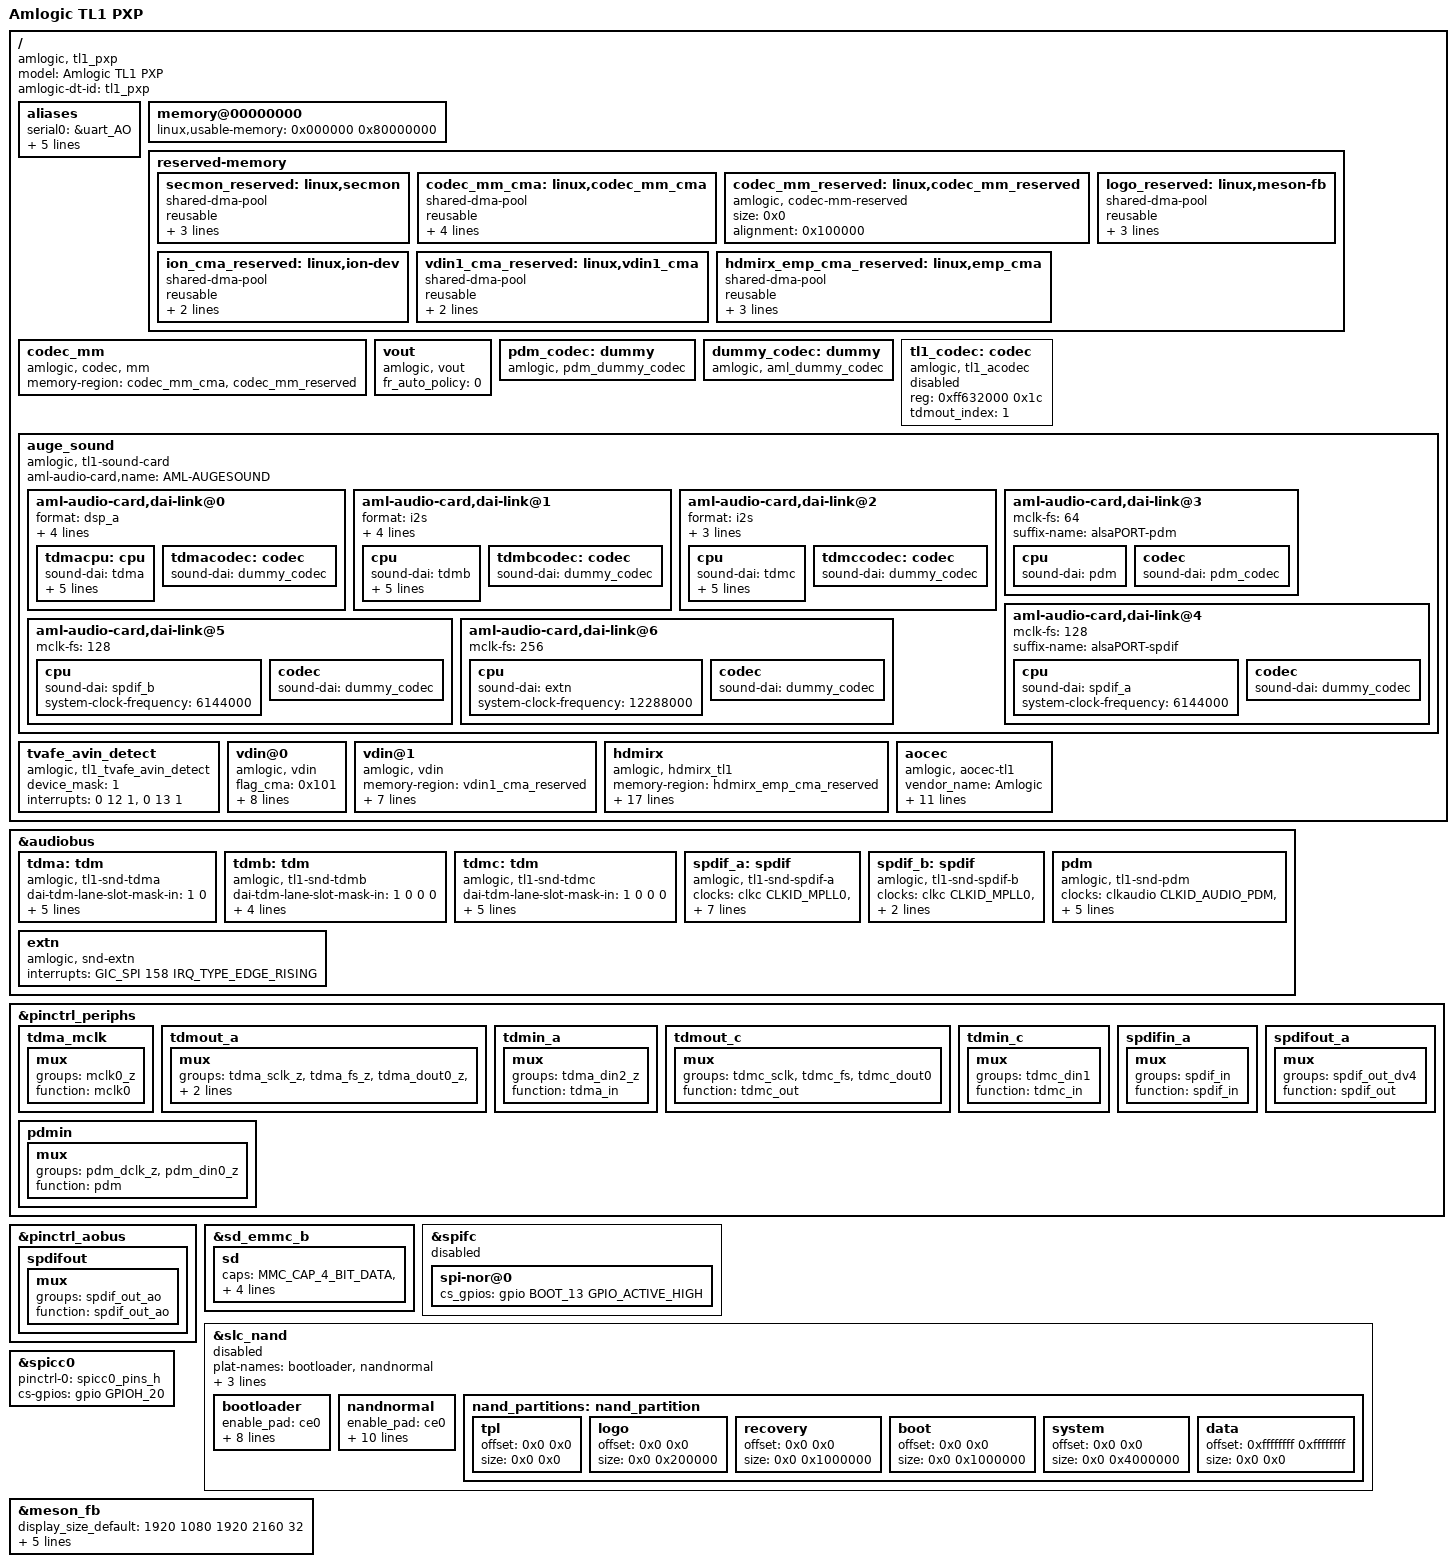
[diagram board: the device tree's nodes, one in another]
/*
 * arch/arm/boot/dts/amlogic/tl1_pxp.dts
 *
 * Copyright (C) 2018 Amlogic, Inc. All rights reserved.
 *
 * This program is free software; you can redistribute it and/or modify
 * it under the terms of the GNU General Public License as published by
 * the Free Software Foundation; either version 2 of the License, or
 * (at your option) any later version.
 *
 * This program is distributed in the hope that it will be useful, but WITHOUT
 * ANY WARRANTY; without even the implied warranty of MERCHANTABILITY or
 * FITNESS FOR A PARTICULAR PURPOSE.  See the GNU General Public License for
 * more details.
 *
 */

/dts-v1/;
#include "mesontl1.dtsi"

/ {
	model = "Amlogic TL1 PXP";
	amlogic-dt-id = "tl1_pxp";
	compatible = "amlogic, tl1_pxp";

	aliases {
		serial0 = &uart_AO;
		i2c0 = &i2c0;
		i2c1 = &i2c1;
		i2c2 = &i2c2;
		i2c3 = &i2c3;
		i2c4 = &i2c_AO;
	};

	memory@00000000 {
		device_type = "memory";
		linux,usable-memory = <0x000000 0x80000000>;
	};

	reserved-memory {
		#address-cells = <1>;
		#size-cells = <1>;
		ranges;
		/* global autoconfigured region for contiguous allocations */
		secmon_reserved: linux,secmon {
			compatible = "shared-dma-pool";
			reusable;
			size = <0x400000>;
			alignment = <0x400000>;
			alloc-ranges = <0x05000000 0x400000>;
		};

		codec_mm_cma:linux,codec_mm_cma {
			compatible = "shared-dma-pool";
			reusable;
			/* ion_codec_mm max can alloc size 80M*/
			size = <0x13400000>;
			alignment = <0x400000>;
			linux,contiguous-region;
			alloc-ranges = <0x30000000 0x50000000>;
		};

		/* codec shared reserved */
		codec_mm_reserved:linux,codec_mm_reserved {
			compatible = "amlogic, codec-mm-reserved";
			size = <0x0>;
			alignment = <0x100000>;
			//no-map;
		};

		logo_reserved:linux,meson-fb {
			compatible = "shared-dma-pool";
			reusable;
			size = <0x800000>;
			alignment = <0x400000>;
			alloc-ranges = <0x7f800000 0x800000>;
		};

		ion_cma_reserved:linux,ion-dev {
			compatible = "shared-dma-pool";
			reusable;
			size = <0x8000000>;
			alignment = <0x400000>;
		};

		/*  vdin0 CMA pool */
		//vdin0_cma_reserved:linux,vdin0_cma {
		//	compatible = "shared-dma-pool";
		//	reusable;
			/* 3840x2160x4x4 ~=128 M */
		//	size = <0xc400000>;
		//	alignment = <0x400000>;
		//};

		/*  vdin1 CMA pool */
		vdin1_cma_reserved:linux,vdin1_cma {
			compatible = "shared-dma-pool";
			reusable;
			/* 1920x1080x2x4  =16 M */
			size = <0x1400000>;
			alignment = <0x400000>;
		};

		/* for hdmi rx emp use */
		hdmirx_emp_cma_reserved:linux,emp_cma {
			compatible = "shared-dma-pool";
			/*linux,phandle = <5>;*/
			reusable;
			/* 2M-30M for emp or tmds to ddr */
			size = <0x01e00000>;
			alignment = <0x10000>;
			alloc-ranges = <0x30000000 0x50000000>;
		};
	}; /* end of reserved-memory */

	codec_mm {
		compatible = "amlogic, codec, mm";
		status = "okay";
		memory-region = <&codec_mm_cma &codec_mm_reserved>;
	};

	vout {
		compatible = "amlogic, vout";
		status = "okay";
		fr_auto_policy = <0>;
	};

	/* Audio Related start */
	pdm_codec:dummy {
		#sound-dai-cells = <0>;
		compatible = "amlogic, pdm_dummy_codec";
		status = "okay";
	};

	dummy_codec:dummy {
		#sound-dai-cells = <0>;
		compatible = "amlogic, aml_dummy_codec";
		status = "okay";
	};

	tl1_codec:codec {
		#sound-dai-cells = <0>;
		compatible = "amlogic, tl1_acodec";
		status = "disabled";
		reg = <0xff632000 0x1c>;
		tdmout_index = <1>;
	};

	auge_sound {
		compatible = "amlogic, tl1-sound-card";
		aml-audio-card,name = "AML-AUGESOUND";

		aml-audio-card,dai-link@0 {
			format = "dsp_a";
			mclk-fs = <512>;
			//continuous-clock;
			//bitclock-inversion;
			//frame-inversion;
			/* master mode */
			bitclock-master = <&tdma>;
			frame-master = <&tdma>;
			/* slave mode */
			/*
			 * bitclock-master = <&tdmacodec>;
			 * frame-master = <&tdmacodec>;
			 */
			/* suffix-name, sync with android audio hal used for */
			suffix-name = "alsaPORT-pcm";
			tdmacpu: cpu {
				sound-dai = <&tdma>;
				dai-tdm-slot-tx-mask =
							<1 1 1 1 1 1 1 1>;
				dai-tdm-slot-rx-mask =
							<1 1 1 1 1 1 1 1>;
				dai-tdm-slot-num = <8>;
				dai-tdm-slot-width = <32>;
				system-clock-frequency = <24576000>;
			};
			tdmacodec: codec {
				sound-dai = <&dummy_codec>;
			};
		};

		aml-audio-card,dai-link@1 {
			format = "i2s";
			mclk-fs = <256>;
			//continuous-clock;
			//bitclock-inversion;
			//frame-inversion;
			/* master mode */
			bitclock-master = <&tdmb>;
			frame-master = <&tdmb>;
			/* slave mode */
			//bitclock-master = <&tdmbcodec>;
			//frame-master = <&tdmbcodec>;
			/* suffix-name, sync with android audio hal used for */
			suffix-name = "alsaPORT-i2s";
			cpu {
				sound-dai = <&tdmb>;
				dai-tdm-slot-tx-mask = <1 1>;
				dai-tdm-slot-rx-mask = <1 1>;
				dai-tdm-slot-num = <2>;
				/*
				 * dai-tdm-slot-tx-mask =
				 *	<1 1 1 1 1 1 1 1>;
				 * dai-tdm-slot-rx-mask =
				 *	<1 1 1 1 1 1 1 1>;
				 * dai-tdm-slot-num = <8>;
				 */
				dai-tdm-slot-width = <32>;
				system-clock-frequency = <12288000>;
			};
			tdmbcodec: codec {
				sound-dai = <&dummy_codec>;
			};
		};

		aml-audio-card,dai-link@2 {
			format = "i2s";
			mclk-fs = <256>;
			//continuous-clock;
			//bitclock-inversion;
			//frame-inversion;
			/* master mode */
			bitclock-master = <&tdmc>;
			frame-master = <&tdmc>;
			/* slave mode */
			//bitclock-master = <&tdmccodec>;
			//frame-master = <&tdmccodec>;
			/* suffix-name, sync with android audio hal used for */
			//suffix-name = "alsaPORT-tdm";
			cpu {
				sound-dai = <&tdmc>;
				dai-tdm-slot-tx-mask = <1 1>;
				dai-tdm-slot-rx-mask = <1 1>;
				dai-tdm-slot-num = <2>;
				dai-tdm-slot-width = <32>;
				system-clock-frequency = <12288000>;
			};
			tdmccodec: codec {
				sound-dai = <&dummy_codec>;
			};
		};

		aml-audio-card,dai-link@3 {
			mclk-fs = <64>;
			/* suffix-name, sync with android audio hal used for */
			suffix-name = "alsaPORT-pdm";
			cpu {
				sound-dai = <&pdm>;
			};
			codec {
				sound-dai = <&pdm_codec>;
			};
		};

		aml-audio-card,dai-link@4 {
			mclk-fs = <128>;
			/* suffix-name, sync with android audio hal used for */
			suffix-name = "alsaPORT-spdif";
			cpu {
				sound-dai = <&spdif_a>;
				system-clock-frequency = <6144000>;
			};
			codec {
				sound-dai = <&dummy_codec>;
			};
		};

		aml-audio-card,dai-link@5 {
			mclk-fs = <128>;
			cpu {
				sound-dai = <&spdif_b>;
				system-clock-frequency = <6144000>;
			};
			codec {
				sound-dai = <&dummy_codec>;
			};
		};

		aml-audio-card,dai-link@6 {
			mclk-fs = <256>;
			cpu {
				sound-dai = <&extn>;
				system-clock-frequency = <12288000>;
			};
			codec {
				sound-dai = <&dummy_codec>;
			};
		};

	};
	/* Audio Related end */

	tvafe_avin_detect {
		compatible = "amlogic, tl1_tvafe_avin_detect";
		status = "okay";
		device_mask = <1>;/*bit0:ch1;bit1:ch2*/
		interrupts = <0 12 1>,
				<0 13 1>;
	};

	vdin@0 {
		compatible = "amlogic, vdin";
		/*memory-region = <&vdin0_cma_reserved>;*/
		status = "okay";
		/*bit0:(1:share with codec_mm;0:cma alone)
		 *bit8:(1:alloc in discontinus way;0:alone in continuous way)
		 */
		flag_cma = <0x101>;
		/*MByte, if 10bit disable: 64M(YUV422),
		 *if 10bit enable: 64*1.5 = 96M(YUV422)
		 *if support 4K2K-YUV444-10bit-WR:3840*2160*4*4 ~= 128M
		 *if support 4K2K-YUV422-10bit-wr:3840*2160*3*4 ~= 96M
		 *if support 4K2K-YUV422-8BIT-WR:3840*2160*2*4 ~= 64M
		 *if support 1080p-YUV422-8BIT-WR:1920*1080*2*4 ~= 16M
		 */
		cma_size = <190>;
		interrupts = <0 83 1>;
		rdma-irq = <2>;
		clocks = <&clkc CLKID_FCLK_DIV5>,
			<&clkc CLKID_VDIN_MEAS_COMP>;
		clock-names = "fclk_div5", "cts_vdin_meas_clk";
		vdin_id = <0>;
		/*vdin write mem color depth support:
		 * bit0:support 8bit
		 * bit1:support 9bit
		 * bit2:support 10bit
		 * bit3:support 12bit
		 * bit4:support yuv422 10bit full pack mode (from txl new add)
		 * bit8:use 8bit  at 4k_50/60hz_10bit
		 * bit9:use 10bit at 4k_50/60hz_10bit
		 */
		tv_bit_mode = <0x215>;
		/* afbce_bit_mode: (amlogic frame buff compression encoder)
		 * 0: normal mode, not use afbce
		 * 1: use afbce non-mmu mode
		 * 2: use afbce mmu mode
		 */
		afbce_bit_mode = <0>;
	};

	vdin@1 {
		compatible = "amlogic, vdin";
		memory-region = <&vdin1_cma_reserved>;
		status = "okay";
		/*bit0:(1:share with codec_mm;0:cma alone)
		 *bit8:(1:alloc in discontinus way;0:alone in continuous way)
		 */
		flag_cma = <0>;
		interrupts = <0 85 1>;
		rdma-irq = <4>;
		clocks = <&clkc CLKID_FCLK_DIV5>,
			<&clkc CLKID_VDIN_MEAS_COMP>;
		clock-names = "fclk_div5", "cts_vdin_meas_clk";
		vdin_id = <1>;
		/*vdin write mem color depth support:
		 *bit0:support 8bit
		 *bit1:support 9bit
		 *bit2:support 10bit
		 *bit3:support 12bit
		 */
		tv_bit_mode = <0x15>;
	};

	hdmirx {
		compatible = "amlogic, hdmirx_tl1";
		#address-cells=<1>;
		#size-cells=<1>;
		memory-region = <&hdmirx_emp_cma_reserved>;
		status = "okay";
		pinctrl-names = "default";
		pinctrl-0 = <&hdmirx_a_mux &hdmirx_b_mux
			&hdmirx_c_mux>;
		repeat = <0>;
		interrupts = <0 56 1>;
		clocks = <&clkc CLKID_HDMIRX_MODET_COMP>,
			   <&clkc CLKID_HDMIRX_CFG_COMP>,
			   <&clkc CLKID_HDMIRX_ACR_COMP>,
			   <&clkc CLKID_HDMIRX_AUDMEAS_COMP>,
			   <&xtal>,
			   <&clkc CLKID_FCLK_DIV5>,
			   <&clkc CLKID_FCLK_DIV7>,
			   <&clkc CLKID_HDCP22_SKP_COMP>,
			   <&clkc CLKID_HDCP22_ESM_COMP>;
		//	   <&clkc CLK_AUD_PLL2FS>,
		//	   <&clkc CLK_AUD_PLL4FS>,
		//	   <&clkc CLK_AUD_OUT>;
		clock-names = "hdmirx_modet_clk",
			"hdmirx_cfg_clk",
				"hdmirx_acr_ref_clk",
				"hdmirx_audmeas_clk",
				"xtal",
				"fclk_div5",
				"fclk_div7",
				"hdcp_rx22_skp",
				"hdcp_rx22_esm";
		//		"hdmirx_aud_pll2fs",
		//		"hdmirx_aud_pll4f",
		//		"clk_aud_out";
		hdmirx_id = <0>;
		en_4k_2_2k = <0>;
		hpd_low_cec_off = <1>;
		/* bit4: enable feature, bit3~0: port number */
		disable_port = <0x0>;
		/* MAP_ADDR_MODULE_CBUS */
		/* MAP_ADDR_MODULE_HIU */
		/* MAP_ADDR_MODULE_HDMIRX_CAPB3 */
		/* MAP_ADDR_MODULE_SEC_AHB */
		/* MAP_ADDR_MODULE_SEC_AHB2 */
		/* MAP_ADDR_MODULE_APB4 */
		/* MAP_ADDR_MODULE_TOP */
		reg = < 0x0 0x0
			0xff63C000 0x2000
			0xffe0d000 0x2000
			0x0 0x0
			0x0 0x0
			0x0 0x0
			0xff610000 0xa000>;
	};

	aocec: aocec {
		compatible = "amlogic, aocec-tl1";
		/*device_name = "aocec";*/
		status = "okay";
		vendor_name = "Amlogic"; /* Max Chars: 8	 */
		/* Refer to the following URL at:
		 * http://standards.ieee.org/develop/regauth/oui/oui.txt
		 */
		vendor_id = <0x000000>;
		product_desc = "TL1"; /* Max Chars: 16	  */
		cec_osd_string = "AML_TV"; /* Max Chars: 14    */
		port_num = <3>;
		ee_cec;
		arc_port_mask = <0x2>;
		interrupts = <0 205 1
					0 199 1>;
		interrupt-names = "hdmi_aocecb","hdmi_aocec";
		pinctrl-names = "default","hdmitx_aocecb","cec_pin_sleep";
		pinctrl-0=<&aoceca_mux>;
		pinctrl-1=<&aocecb_mux>;
		pinctrl-2=<&aoceca_mux>;
		reg = <0xFF80023c 0x4
			   0xFF800000 0x400>;
		reg-names = "ao_exit","ao";
	};

}; /* end of / */

&audiobus {
	tdma:tdm {
		compatible = "amlogic, tl1-snd-tdma";
		#sound-dai-cells = <0>;

		dai-tdm-lane-slot-mask-in = <1 0>;
		dai-tdm-lane-slot-mask-out = <1 0>;
		dai-tdm-clk-sel = <0>;

		clocks = <&clkaudio CLKID_AUDIO_MCLK_A
				&clkc CLKID_MPLL0>;
		clock-names = "mclk", "clk_srcpll";

		pinctrl-names = "tdm_pins";
		pinctrl-0 = <&tdma_mclk &tdmout_a &tdmin_a>;

		status = "okay";
	};

	tdmb:tdm {
		compatible = "amlogic, tl1-snd-tdmb";
		#sound-dai-cells = <0>;

		dai-tdm-lane-slot-mask-in = <1 0 0 0>;
		dai-tdm-lane-slot-mask-out = <1 0 0 0>;
		dai-tdm-clk-sel = <1>;

		clocks = <&clkaudio CLKID_AUDIO_MCLK_B
				&clkc CLKID_MPLL1>;
		clock-names = "mclk", "clk_srcpll";

		status = "okay";
	};

	tdmc:tdm {
		compatible = "amlogic, tl1-snd-tdmc";
		#sound-dai-cells = <0>;

		dai-tdm-lane-slot-mask-in = <1 0 0 0>;
		dai-tdm-lane-slot-mask-out = <1 0 0 0>;
		dai-tdm-clk-sel = <2>;

		clocks = <&clkaudio CLKID_AUDIO_MCLK_C
				&clkc CLKID_MPLL2>;
		clock-names = "mclk", "clk_srcpll";

		pinctrl-names = "tdm_pins";
		pinctrl-0 = <&tdmout_c &tdmin_c>;

		status = "okay";
	};

	spdif_a:spdif {
		compatible = "amlogic, tl1-snd-spdif-a";
		#sound-dai-cells = <0>;

		clocks = <&clkc CLKID_MPLL0
				&clkc CLKID_FCLK_DIV4
				&clkaudio CLKID_AUDIO_SPDIFIN
				&clkaudio CLKID_AUDIO_SPDIFOUT
				&clkaudio CLKID_AUDIO_SPDIFIN_CTRL
				&clkaudio CLKID_AUDIO_SPDIFOUT_CTRL>;
		clock-names = "sysclk", "fixed_clk", "gate_spdifin",
				"gate_spdifout", "clk_spdifin", "clk_spdifout";

		interrupts =
				<GIC_SPI 151 IRQ_TYPE_EDGE_RISING>;
		interrupt-names = "irq_spdifin";

		pinctrl-names = "spdif_pins";
		pinctrl-0 = <&spdifout_a &spdifin_a>;

		status = "okay";
	};

	spdif_b:spdif {
		compatible = "amlogic, tl1-snd-spdif-b";
		#sound-dai-cells = <0>;

		clocks = <&clkc CLKID_MPLL0 /*CLKID_HIFI_PLL*/
				&clkaudio CLKID_AUDIO_SPDIFOUTB
				&clkaudio CLKID_AUDIO_SPDIFOUTB_CTRL>;
		clock-names = "sysclk",
				"gate_spdifout", "clk_spdifout";

		status = "okay";
	};

	pdm:pdm {
		compatible = "amlogic, tl1-snd-pdm";
		#sound-dai-cells = <0>;

		clocks = <&clkaudio CLKID_AUDIO_PDM
			&clkc CLKID_FCLK_DIV3
			&clkc CLKID_MPLL3
			&clkaudio CLKID_AUDIO_PDMIN0
			&clkaudio CLKID_AUDIO_PDMIN1>;
		clock-names = "gate",
			"sysclk_srcpll",
			"dclk_srcpll",
			"pdm_dclk",
			"pdm_sysclk";

		pinctrl-names = "pdm_pins";
		pinctrl-0 = <&pdmin>;

		/* mode 0~4, defalut:1 */
		filter_mode = <1>;

		status = "okay";
	};

	extn:extn {
		compatible = "amlogic, snd-extn";
		#sound-dai-cells = <0>;

		interrupts =
				<GIC_SPI 158 IRQ_TYPE_EDGE_RISING>;
		interrupt-names = "irq_frhdmirx";

		status = "okay";
	};

}; /* end of audiobus */

&pinctrl_periphs {
	/* audio pin mux */

	tdma_mclk: tdma_mclk {
		mux { /* GPIOZ_0 */
			groups = "mclk0_z";
			function = "mclk0";
		};
	};

	tdmout_a: tdmout_a {
		mux { /* GPIOZ_1, GPIOZ_2, GPIOZ_3, GPIOZ_5, GPIOZ_6 */
			groups = "tdma_sclk_z",
				"tdma_fs_z",
				"tdma_dout0_z",
				"tdma_dout2_z",
				"tdma_dout3_z";
			function = "tdma_out";
		};
	};

	tdmin_a: tdmin_a {
		mux { /* GPIOZ_9 */
			groups = "tdma_din2_z";
			function = "tdma_in";
		};
	};

	tdmout_c: tdmout_c {
		mux { /* GPIODV_7, GPIODV_8, GPIODV_9 */
			groups = "tdmc_sclk",
				"tdmc_fs",
				"tdmc_dout0";
			function = "tdmc_out";
		};
	};

	tdmin_c: tdmin_c {
		mux { /* GPIODV_10 */
			groups = "tdmc_din1";
			function = "tdmc_in";
		};
	};

	spdifin_a: spdifin_a {
		mux { /* GPIODV_5 */
			groups = "spdif_in";
			function = "spdif_in";
		};
	};

	spdifout_a: spdifout_a {
		mux { /* GPIODV_4 */
			groups = "spdif_out_dv4";
			function = "spdif_out";
		};
	};

	pdmin: pdmin {
		mux { /* GPIOZ_7, GPIOZ_8*/
			groups = "pdm_dclk_z",
				"pdm_din0_z";
			function = "pdm";
		};
	};


}; /* end of pinctrl_periphs */

&pinctrl_aobus {
	spdifout: spdifout {
		mux { /* gpiao_10 */
			groups = "spdif_out_ao";
			function = "spdif_out_ao";
		};
	};
};  /* end of pinctrl_aobus */

&sd_emmc_b {
	status = "okay";
	sd {
		caps = "MMC_CAP_4_BIT_DATA",
			"MMC_CAP_MMC_HIGHSPEED",
			"MMC_CAP_SD_HIGHSPEED",
			"MMC_CAP_NONREMOVABLE"; /**ptm debug */
		f_min = <400000>;
		f_max = <200000000>;
	};
};

&spifc {
	status = "disabled";
	spi-nor@0 {
		cs_gpios = <&gpio BOOT_13 GPIO_ACTIVE_HIGH>;
	};
};

&slc_nand {
	status = "disabled";
	plat-names = "bootloader", "nandnormal";
	plat-num = <2>;
	plat-part-0 = <&bootloader>;
	plat-part-1 = <&nandnormal>;
	bootloader: bootloader{
		enable_pad = "ce0";
		busy_pad = "rb0";
		timming_mode = "mode5";
		bch_mode = "bch8_1k";
		t_rea = <20>;
		t_rhoh = <15>;
		chip_num = <1>;
		part_num = <0>;
		rb_detect = <1>;
	};
	nandnormal: nandnormal{
		enable_pad = "ce0";
		busy_pad = "rb0";
		timming_mode = "mode5";
		bch_mode = "bch8_1k";
		plane_mode = "twoplane";
		t_rea = <20>;
		t_rhoh = <15>;
		chip_num = <2>;
		part_num = <3>;
		partition = <&nand_partitions>;
		rb_detect = <1>;
	};
	nand_partitions:nand_partition{
		/*
		 * if bl_mode is 1, tpl size was generate by
		 * fip_copies * fip_size which
		 * will not skip bad when calculating
		 * the partition size;
		 *
		 * if bl_mode is 0,
		 * tpl partition must be comment out.
		 */
		tpl{
			offset=<0x0 0x0>;
			size=<0x0 0x0>;
		};
		logo{
			offset=<0x0 0x0>;
			size=<0x0 0x200000>;
		};
		recovery{
			offset=<0x0 0x0>;
			size=<0x0 0x1000000>;
		};
		boot{
			offset=<0x0 0x0>;
			size=<0x0 0x1000000>;
		};
		system{
			offset=<0x0 0x0>;
			size=<0x0 0x4000000>;
		};
		data{
			offset=<0xffffffff 0xffffffff>;
			size=<0x0 0x0>;
		};
	};
};

&spicc0 {
	status = "okay";
	pinctrl-names = "default";
	pinctrl-0 = <&spicc0_pins_h>;
	cs-gpios = <&gpio GPIOH_20 0>;
};

&meson_fb {
	status = "okay";
	display_size_default = <1920 1080 1920 2160 32>;
	mem_size = <0x00800000 0x1980000 0x100000 0x800000>;
	logo_addr = "0x7f800000";
	mem_alloc = <1>;
	pxp_mode = <1>; /** 0:normal mode 1:pxp mode */
};
